# ESP32S31_RADIO register map
Vendor: Espressif; Series: ESP32-S31; File version: 3.52
Registers are 32-bit, read-write, no defined reset value unless marked. A register's access mark holds for its fields unless they carry their own. Offsets are from the block's base; [hi:lo] are bit positions; {n}, {i} and the like mark numbered series.

## PHY_BASEBAND_CONFIG_ORACLE — PHY/baseband configuration registers recovered from complete rev0 ROM bodies and complete pinned libphy leaves. Operation-derived fields keep UNKNOWN where neither public documentation nor an independent symbol establishes the electrical meaning.
Base 0x20100000
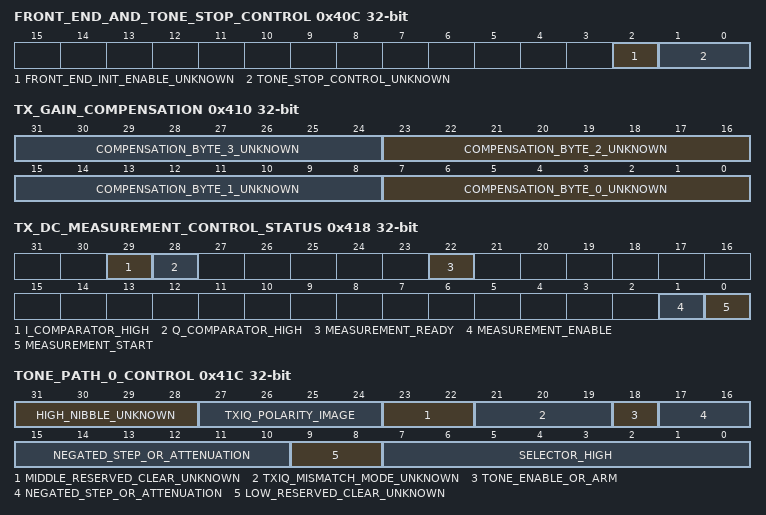
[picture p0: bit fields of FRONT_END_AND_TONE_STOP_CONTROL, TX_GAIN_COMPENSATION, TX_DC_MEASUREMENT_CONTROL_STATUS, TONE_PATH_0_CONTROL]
0x40C FRONT_END_AND_TONE_STOP_CONTROL — Shared word whose bit 2 is set by complete phy_fe_reg_init. Complete phy_start_tx_tone_step clears bits 1:0 and complete phy_stop_tx_tone sets them.
  [2] FRONT_END_INIT_ENABLE_UNKNOWN
  [1:0] TONE_STOP_CONTROL_UNKNOWN — Two-bit field cleared before the ROM power-control tone and set by its complete cleanup; the individual bit meanings are unknown.
0x410 TX_GAIN_COMPENSATION — Complete phy_txgain_comp_pacfg_new(1) publishes four ordered byte updates.
  [8n+7:8n] COMPENSATION_BYTE_{n}_UNKNOWN (n=0..3)
0x414 TX_GAIN_COMPENSATION_AUX wo — Pinned libphy.a[phy_reg.o] phy_start_tx_tone_step_new writes the full zero image while disabling TX-gain compensation.
  [31:0] AUXILIARY_IMAGE_UNKNOWN
0x418 TX_DC_MEASUREMENT_CONTROL_STATUS — Complete phy_txdc_cal triggers measurement with bits 1 and 0, polls ready bit 22, samples I and Q comparator bits 29 and 28 through independent reads, then clears bits 1 and 0.
  [29] I_COMPARATOR_HIGH ro, [28] Q_COMPARATOR_HIGH ro, [22] MEASUREMENT_READY ro, [1] MEASUREMENT_ENABLE, [0] MEASUREMENT_START
0x41C TONE_PATH_0_CONTROL — First calibration-tone path word. Complete source bodies prove the packed selector, negated step or attenuation, enable/arm bit and TX-IQ mismatch images; the high nibble is preserved and remains electrically unknown.
  [31:28] HIGH_NIBBLE_UNKNOWN — High nibble preserved by all recovered tone updates and retained by the TX-IQ save/restore transaction.
  [27:24] TXIQ_POLARITY_IMAGE — Four-bit mismatch polarity image: first configuration writes bit 26, while the second phase writes nibble 1 or 8.
  [23:22] MIDDLE_RESERVED_CLEAR_UNKNOWN — Complete general and first-polarity tone writers clear these bits.
  [21:19] TXIQ_MISMATCH_MODE_UNKNOWN — Three-bit image set to binary 101 for the first mismatch-power polarity and otherwise cleared by general tone setup.
  [18] TONE_ENABLE_OR_ARM — Set by tone start and by each PWDET sample-arm edge; cleared by stop and sample cleanup.
  [17:10] NEGATED_STEP_OR_ATTENUATION — Two's-complement negated eight-bit tone step or attenuation.
  [9:8] LOW_RESERVED_CLEAR_UNKNOWN — Complete tone writers clear these bits; their hardware meaning is unknown.
  [7:0] SELECTOR_HIGH — Upper eight bits of the evidenced ten-bit selector; bits 1:0 are in TONE_SELECTOR_CONTROL.
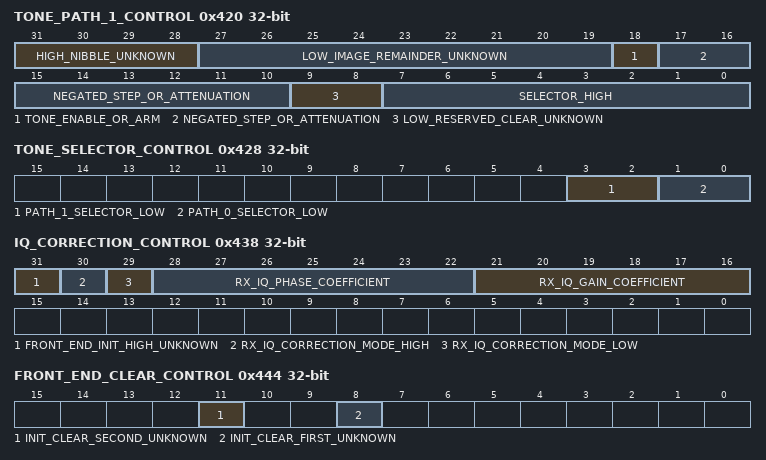
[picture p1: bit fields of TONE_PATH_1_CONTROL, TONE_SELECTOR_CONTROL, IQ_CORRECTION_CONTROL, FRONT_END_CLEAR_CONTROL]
0x420 TONE_PATH_1_CONTROL — Second calibration-tone path word. All currently evidenced calls publish a disabled zero low image while preserving the high nibble.
  [31:28] HIGH_NIBBLE_UNKNOWN — High nibble preserved by all recovered second-path tone updates.
  [27:19] LOW_IMAGE_REMAINDER_UNKNOWN
    0=CLEARED
  [18] TONE_ENABLE_OR_ARM
  [17:10] NEGATED_STEP_OR_ATTENUATION
    0=CLEARED
  [9:8] LOW_RESERVED_CLEAR_UNKNOWN
    0=CLEARED
  [7:0] SELECTOR_HIGH
    0=CLEARED
0x424 RX_GAIN_DC_CONTROL — Complete rev0 ROM phy_set_rx_gain_cal_dc at 0x2f829858, size 0x206, sets bits 6:5 before the bounded RX-gain DC calibration graph and clears the same pair during the common cleanup tail. Their narrower electrical meaning is not independently proved.
  [6:5] CALIBRATION_ENABLE_UNKNOWN
    0=DISABLED (Common phy_set_rx_gain_cal_dc cleanup value.); 3=ENABLED (phy_set_rx_gain_cal_dc calibration-prefix value.)
0x428 TONE_SELECTOR_CONTROL — Low two selector bits for each calibration-tone path, updated through separate fresh-read edges.
  [3:2] PATH_1_SELECTOR_LOW, [1:0] PATH_0_SELECTOR_LOW
0x438 IQ_CORRECTION_CONTROL — Shared RX-IQ coefficient and correction-mode word.
  [31] FRONT_END_INIT_HIGH_UNKNOWN — Complete phy_fe_reg_init sets bit 31 after the repeated ADC-control writes.
  [30] RX_IQ_CORRECTION_MODE_HIGH — High bit of the correction-mode field updated through a distinct fresh-read edge by the RXIQ parent.
  [29] RX_IQ_CORRECTION_MODE_LOW — Low bit of the correction-mode field updated through a distinct fresh-read edge by the RXIQ parent.
  [28:22] RX_IQ_PHASE_COEFFICIENT
  [21:16] RX_IQ_GAIN_COEFFICIENT
0x444 FRONT_END_CLEAR_CONTROL — Complete phy_fe_reg_init clears bits 8 and 11 in two separately ordered RMW edges.
  [11] INIT_CLEAR_SECOND_UNKNOWN, [8] INIT_CLEAR_FIRST_UNKNOWN
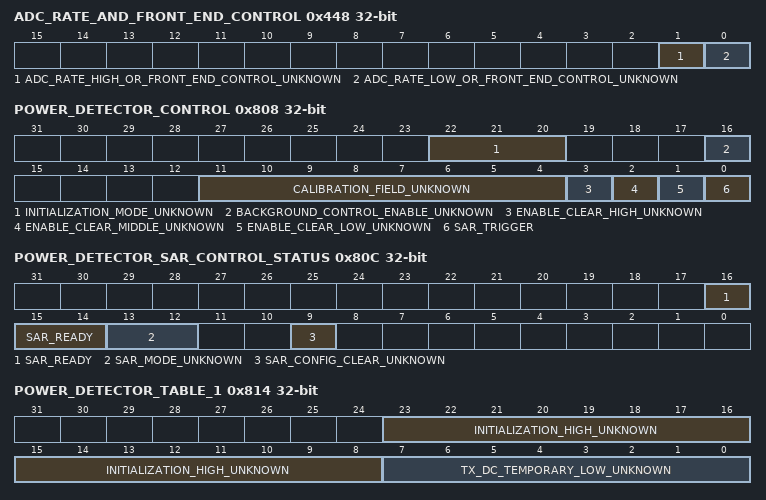
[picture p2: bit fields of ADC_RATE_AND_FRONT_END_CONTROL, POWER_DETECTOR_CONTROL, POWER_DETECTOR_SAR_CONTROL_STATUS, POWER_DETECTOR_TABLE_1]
0x448 ADC_RATE_AND_FRONT_END_CONTROL — Complete phy_adc_rate_set and phy_dac_rate_set publish rate bit zero into bits 1 and 0 through separate RMW edges. Front-end initialization and update set the same bits in their independently evidenced order.
  [1] ADC_RATE_HIGH_OR_FRONT_END_CONTROL_UNKNOWN, [0] ADC_RATE_LOW_OR_FRONT_END_CONTROL_UNKNOWN
0x808 POWER_DETECTOR_CONTROL — Shared PWDET trigger, calibration and background-control word.
  [22:20] INITIALIZATION_MODE_UNKNOWN, [16] BACKGROUND_CONTROL_ENABLE_UNKNOWN, [11:4] CALIBRATION_FIELD_UNKNOWN, [3] ENABLE_CLEAR_HIGH_UNKNOWN, [2] ENABLE_CLEAR_MIDDLE_UNKNOWN, [1] ENABLE_CLEAR_LOW_UNKNOWN, [0] SAR_TRIGGER
0x80C POWER_DETECTOR_SAR_CONTROL_STATUS — PWDET SAR configuration and three-bit ready status.
  [16:14] SAR_READY ro — Hardware completion state sampled by the complete power-detector paths; neither source writes these bits.
  [13:12] SAR_MODE_UNKNOWN
  [9] SAR_CONFIG_CLEAR_UNKNOWN
0x810 POWER_DETECTOR_TABLE_0_OPAQUE wo — Complete phy_pwdet_reg_init writes 0x0f0f0fff.
0x814 POWER_DETECTOR_TABLE_1 — Complete initialization writes 0x00ff0f64; TX-DC calibration temporarily replaces the low byte.
  [23:8] INITIALIZATION_HIGH_UNKNOWN, [7:0] TX_DC_TEMPORARY_LOW_UNKNOWN
0x818 POWER_DETECTOR_REFERENCE wo — PWDET reference word; initialization writes 0xaaaa and later paths publish 0, 0x5555 or 0xaaaa.
  [15:0] REFERENCE_CODE
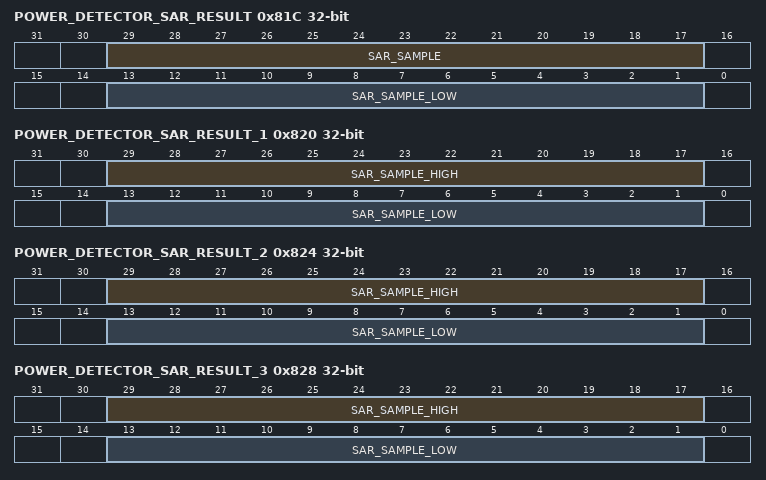
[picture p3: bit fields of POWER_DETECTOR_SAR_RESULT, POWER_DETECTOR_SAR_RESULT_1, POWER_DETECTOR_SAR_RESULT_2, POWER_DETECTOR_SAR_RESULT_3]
0x81C POWER_DETECTOR_SAR_RESULT ro — First of four consecutive SAR result words. phy_get_tone_sar_dout_ consumes its upper thirteen-bit sample; phy_get_fm_sar_dout consumes both thirteen-bit halves from all four words.
  [29:17] SAR_SAMPLE, [13:1] SAR_SAMPLE_LOW
0x820 POWER_DETECTOR_SAR_RESULT_1 ro — Second of four consecutive dual thirteen-bit SAR result words consumed by complete phy_get_fm_sar_dout.
  [29:17] SAR_SAMPLE_HIGH, [13:1] SAR_SAMPLE_LOW
0x824 POWER_DETECTOR_SAR_RESULT_2 ro — Third of four consecutive dual thirteen-bit SAR result words consumed by complete phy_get_fm_sar_dout.
  [29:17] SAR_SAMPLE_HIGH, [13:1] SAR_SAMPLE_LOW
0x828 POWER_DETECTOR_SAR_RESULT_3 ro — Fourth of four consecutive dual thirteen-bit SAR result words consumed by complete phy_get_fm_sar_dout.
  [29:17] SAR_SAMPLE_HIGH, [13:1] SAR_SAMPLE_LOW
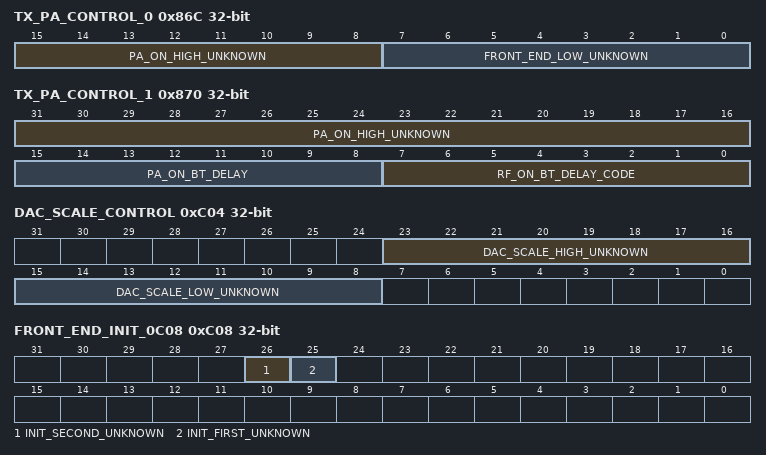
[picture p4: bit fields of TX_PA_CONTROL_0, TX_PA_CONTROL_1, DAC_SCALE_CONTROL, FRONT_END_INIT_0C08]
0x86C TX_PA_CONTROL_0 — Shared front-end low byte and PA-on high byte.
  [15:8] PA_ON_HIGH_UNKNOWN, [7:0] FRONT_END_LOW_UNKNOWN
0x870 TX_PA_CONTROL_1 — Complete phy_tx_paon_set publishes 0x0a0e in the high half and 0xc8 in byte one. Complete ble_tx_config_check independently names the low two bytes as Bluetooth RF/PA turn-on delays.
  [31:16] PA_ON_HIGH_UNKNOWN
  [15:8] PA_ON_BT_DELAY — Bluetooth PA-on delay.
  [7:0] RF_ON_BT_DELAY_CODE — Eight-bit RF-on delay code printed by the vendor checker after integer division by 80. The electrical time unit of the raw code is not otherwise assumed.
0xC04 DAC_SCALE_CONTROL — Complete ROM tone start clears both byte-wide DAC-scale fields before measurement; complete phy_stop_tx_tone(1) restores both fields to 0xff through separate fresh-read writes.
  [23:16] DAC_SCALE_HIGH_UNKNOWN, [15:8] DAC_SCALE_LOW_UNKNOWN
0xC08 FRONT_END_INIT_0C08 — Both complete source bodies set bit 25 and then bit 26 through separate fresh-read RMW edges.
  [26] INIT_SECOND_UNKNOWN, [25] INIT_FIRST_UNKNOWN
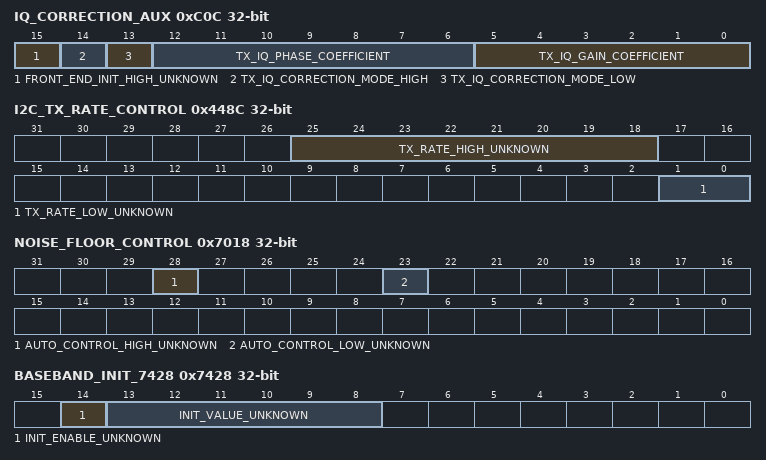
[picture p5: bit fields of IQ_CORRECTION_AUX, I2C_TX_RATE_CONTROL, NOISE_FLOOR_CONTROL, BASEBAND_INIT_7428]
0xC0C IQ_CORRECTION_AUX — Shared TX-IQ coefficient and correction-mode word.
  [15] FRONT_END_INIT_HIGH_UNKNOWN — Complete phy_fe_reg_init sets bit 15 after the shared correction-mode initialization.
  [14] TX_IQ_CORRECTION_MODE_HIGH — High bit of the auxiliary correction-mode field updated through a distinct fresh-read edge by the RXIQ parent.
  [13] TX_IQ_CORRECTION_MODE_LOW — Low bit of the auxiliary correction-mode field updated through a distinct fresh-read edge by the RXIQ parent.
  [12:6] TX_IQ_PHASE_COEFFICIENT
  [5:0] TX_IQ_GAIN_COEFFICIENT
0xC20 FRONT_END_INIT_0C20 — Final complete phy_fe_reg_init RMW replaces the low byte with 0x57.
  [7:0] INIT_LOW_UNKNOWN
0x448C I2C_TX_RATE_CONTROL — Complete phy_i2c_txrate_init replaces both evidenced rate fields before dispatching TX-gain compensation.
  [25:18] TX_RATE_HIGH_UNKNOWN, [1:0] TX_RATE_LOW_UNKNOWN
0x7018 NOISE_FLOOR_CONTROL — Complete phy_noise_floor_auto_set sets both control bits.
  [28] AUTO_CONTROL_HIGH_UNKNOWN, [23] AUTO_CONTROL_LOW_UNKNOWN
0x708C NOISE_FLOOR_MEASUREMENT ro — Complete phy_read_hw_noisefloor reads this word once, sign-extends the low twelve-bit two's-complement value and divides it arithmetically by four to produce its quarter-dB result. Higher bits are not consumed. Open rev0 HIL read a stable -92 dBm whole-unit result through the complete ROM plus wDev transform.
  [11:0] SIGNED_SIXTEENTH_DB_CODE — Signed twelve-bit noise-floor measurement in sixteenth-dB units. The complete ROM arithmetic shift produces quarter-dB and wDev_GetNoiseFloor applies rounded division by four once more before retaining a signed byte; open rev0 HIL observed -92 dBm.
0x7400 BASEBAND_INIT_7400 — Complete phy_bb_reg_init sets bits 14:13.
  [14:13] INIT_UNKNOWN
0x7428 BASEBAND_INIT_7428 — Complete phy_bb_reg_init sets bit 14 and replaces bits 13:8 with 0x15.
  [14] INIT_ENABLE_UNKNOWN, [13:8] INIT_VALUE_UNKNOWN
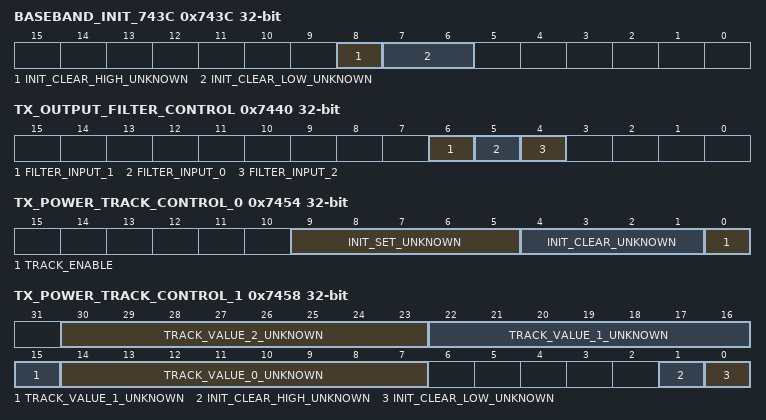
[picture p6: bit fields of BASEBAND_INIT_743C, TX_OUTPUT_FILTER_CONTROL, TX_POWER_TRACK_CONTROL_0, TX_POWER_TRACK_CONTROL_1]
0x743C BASEBAND_INIT_743C — Complete phy_bb_reg_init clears bits 8:6 through two fresh-read updates.
  [8] INIT_CLEAR_HIGH_UNKNOWN, [7:6] INIT_CLEAR_LOW_UNKNOWN
0x7440 TX_OUTPUT_FILTER_CONTROL — Complete phy_bbtx_outfilter replaces bits five, six and four through three independent fresh-read RMWs.
  [6] FILTER_INPUT_1, [5] FILTER_INPUT_0, [4] FILTER_INPUT_2
0x7454 TX_POWER_TRACK_CONTROL_0 — Complete phy_bb_txpwr_track publishes enable plus two initialization fields.
  [9:5] INIT_SET_UNKNOWN, [4:1] INIT_CLEAR_UNKNOWN, [0] TRACK_ENABLE
0x7458 TX_POWER_TRACK_CONTROL_1 — Complete phy_bb_txpwr_track clears bits 1:0 and publishes three eight-bit tracking values.
  [30:23] TRACK_VALUE_2_UNKNOWN, [22:15] TRACK_VALUE_1_UNKNOWN, [14:7] TRACK_VALUE_0_UNKNOWN, [1] INIT_CLEAR_HIGH_UNKNOWN, [0] INIT_CLEAR_LOW_UNKNOWN
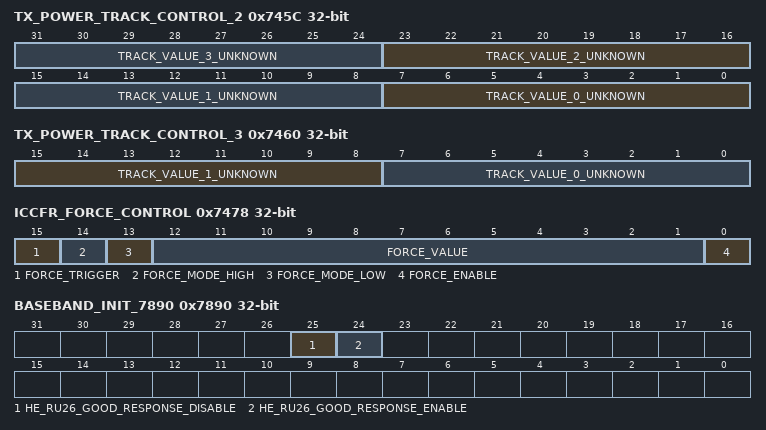
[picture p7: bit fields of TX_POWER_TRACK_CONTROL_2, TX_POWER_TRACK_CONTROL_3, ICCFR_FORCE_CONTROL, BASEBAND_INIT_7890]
0x745C TX_POWER_TRACK_CONTROL_2 — Complete phy_bb_txpwr_track publishes four byte-wide tracking values.
  [8n+7:8n] TRACK_VALUE_{n}_UNKNOWN (n=0..3)
0x7460 TX_POWER_TRACK_CONTROL_3 — Complete phy_bb_txpwr_track publishes two byte-wide tracking values.
  [15:8] TRACK_VALUE_1_UNKNOWN, [7:0] TRACK_VALUE_0_UNKNOWN
0x7468 HCCFR_CONTROL — Complete phy_config_hccfr replaces bit 22 with the low bit of its first argument.
  [22] ENABLE — Complete phy_config_hccfr writes zero to disable HCCFR and one to enable it.
    0=DISABLED (Disable HCCFR processing.); 1=ENABLED (Enable HCCFR processing.)
0x746C HCCFR_VALUE — Complete phy_config_hccfr replaces the low twelve bits with its second argument.
  [11:0] VALUE — Complete phy_config_hccfr retains the caller value to this twelve-bit field; every representable field image is accepted by the recovered leaf.
0x7478 ICCFR_FORCE_CONTROL — Complete phy_force_iccfr publishes five fields through five separately ordered fresh-read RMWs.
  [15] FORCE_TRIGGER
  [14] FORCE_MODE_HIGH
  [13] FORCE_MODE_LOW
  [12:1] FORCE_VALUE — Complete phy_force_iccfr retains the caller value to this twelve-bit field; every representable field image is accepted by the recovered leaf.
  [0] FORCE_ENABLE — Complete phy_force_iccfr writes zero to disable the forced ICCFR value and one to enable it.
    0=DISABLED (Use the ordinary ICCFR value path.); 1=ENABLED (Use the forced ICCFR value.)
0x747C ICCFR_ENABLE_CONTROL — Complete phy_iccfr_en writes three to bits 26:25 for a zero argument and clears them for a nonzero argument.
  [26:25] GATE — Complete phy_iccfr_en writes zero for a nonzero enable input and three for a zero input; the other two encodings are not evidenced.
    0=ENABLED (Enable ICCFR through the recovered zero gate image.); 3=DISABLED (Disable ICCFR through the recovered all-ones gate image.)
0x7808 BASEBAND_INIT_7808 — Complete phy_bb_reg_init replaces bits 13:7 with 0x60.
  [13:7] INIT_VALUE_UNKNOWN
0x7890 BASEBAND_INIT_7890 — Complete phy_bb_reg_init and phy_hemu_ru26_good_res both clear bit 25 then set bit 24 through separate fresh-read RMWs.
  [25] HE_RU26_GOOD_RESPONSE_DISABLE, [24] HE_RU26_GOOD_RESPONSE_ENABLE
0x78DC BASEBAND_INIT_78DC — Complete phy_bb_reg_init replaces bits 13:7 with two.
  [13:7] INIT_VALUE_UNKNOWN
0x78E4 BASEBAND_INIT_78E4 — Complete phy_bb_reg_init clears bit 22.
  [22] INIT_CLEAR_UNKNOWN
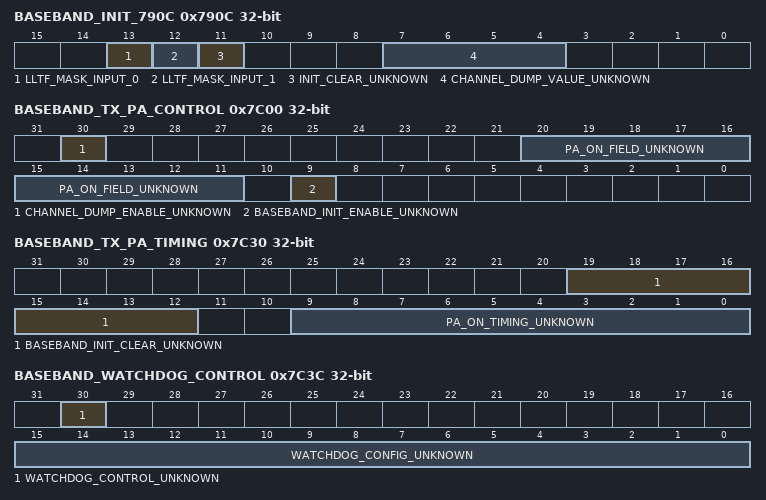
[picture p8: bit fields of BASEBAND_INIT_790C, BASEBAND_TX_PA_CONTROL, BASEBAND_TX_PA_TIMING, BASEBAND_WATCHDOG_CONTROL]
0x790C BASEBAND_INIT_790C — Complete phy_bb_reg_init clears bit 11; complete phy_lltf_mask_en independently replaces bits thirteen and twelve; complete phy_chan_dump_cfg replaces bits 7:4 and bit 11 through separate fresh-read RMWs.
  [13] LLTF_MASK_INPUT_0
  [12] LLTF_MASK_INPUT_1
  [11] INIT_CLEAR_UNKNOWN
  [7:4] CHANNEL_DUMP_VALUE_UNKNOWN — Complete phy_chan_dump_cfg replaces bits 7:4 with the low nibble of its first argument.
0x7980 BASEBAND_INIT_7980 — Complete phy_bb_reg_init clears bit 25.
  [25] INIT_CLEAR_UNKNOWN
0x7A28 BASEBAND_INIT_7A28 — Complete phy_bb_reg_init clears bit 22.
  [22] INIT_CLEAR_UNKNOWN
0x7C00 BASEBAND_TX_PA_CONTROL — Complete phy_bb_reg_init sets bit 9; complete phy_tx_paon_set replaces bits 20:11; complete phy_chan_dump_cfg replaces bit 30 with the low bit of its second argument.
  [30] CHANNEL_DUMP_ENABLE_UNKNOWN — Complete phy_chan_dump_cfg replaces bit 30 with the low bit of its second argument.
  [20:11] PA_ON_FIELD_UNKNOWN
  [9] BASEBAND_INIT_ENABLE_UNKNOWN
0x7C08 BASEBAND_WATCHDOG_STATUS ro — Complete phy_bb_wdt_get_status returns one unrestricted full-word read.
  [31:0] STATUS — Complete unrestricted watchdog status value returned by phy_bb_wdt_get_status.
0x7C30 BASEBAND_TX_PA_TIMING — Complete phy_bb_reg_init clears bits 19:12; complete phy_tx_paon_set replaces bits 9:0 with 0x1e.
  [19:12] BASEBAND_INIT_CLEAR_UNKNOWN, [9:0] PA_ON_TIMING_UNKNOWN
0x7C3C BASEBAND_WATCHDOG_CONTROL — Complete phy_bb_wdg_cfg publishes low configuration 0x00aa and sets bit 30.
  [30] WATCHDOG_CONTROL_UNKNOWN, [15:0] WATCHDOG_CONFIG_UNKNOWN
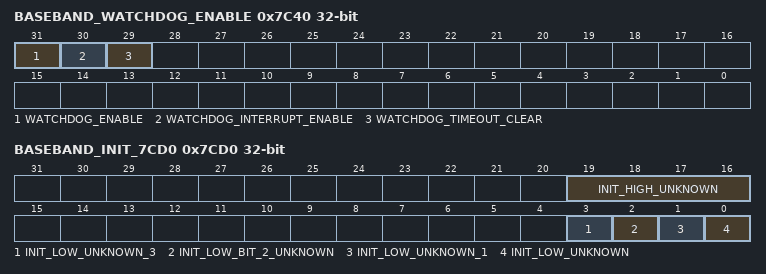
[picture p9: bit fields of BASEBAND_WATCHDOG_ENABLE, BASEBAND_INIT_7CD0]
0x7C40 BASEBAND_WATCHDOG_ENABLE — Complete phy_bb_wdg_cfg sets bit 31. The standalone watchdog leaves replace bits 31 and 30 and set timeout-clear bit 29.
  [31] WATCHDOG_ENABLE, [30] WATCHDOG_INTERRUPT_ENABLE, [29] WATCHDOG_TIMEOUT_CLEAR
0x7C44 NOISE_FLOOR_ENABLE_0 — Complete phy_noise_floor_auto_set sets bit zero.
  [0] AUTO_ENABLE_UNKNOWN
0x7C50 NOISE_FLOOR_ENABLE_1 — Complete phy_noise_floor_auto_set sets bit zero.
  [0] AUTO_ENABLE_UNKNOWN
0x7C6C TX_PA_TABLE_OPAQUE wo — Complete phy_tx_paon_set writes 0x0661a45f.
0x7CA8 BASEBAND_INIT_7CA8 — Complete phy_bb_reg_init sets bit 20.
  [20] INIT_ENABLE_UNKNOWN
0x7CD0 BASEBAND_INIT_7CD0 — Complete phy_bb_reg_init sets both nibbles to 0xf; complete phy_btbb_wifi_bb_cfg2 preserves low bit two, sets the other low bits and sets the high nibble.
  [19:16] INIT_HIGH_UNKNOWN
  [3] INIT_LOW_UNKNOWN_3
  [2] INIT_LOW_BIT_2_UNKNOWN — Complete phy_btbb_wifi_bb_cfg2 preserves this bit while setting the other low-nibble bits.
  [1] INIT_LOW_UNKNOWN_1
  [0] INIT_LOW_UNKNOWN
